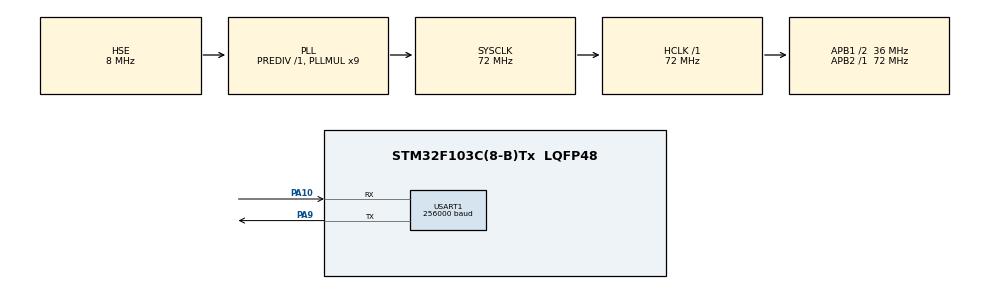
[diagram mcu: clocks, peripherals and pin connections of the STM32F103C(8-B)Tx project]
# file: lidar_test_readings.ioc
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Mcu.Family=STM32F1
Mcu.Name=STM32F103C(8-B)Tx
Mcu.Package=LQFP48
NVIC.PriorityGroup=NVIC_PRIORITYGROUP_4
NVIC.USART1_IRQn=true\:0\:0\:false\:false\:true\:true\:true
PA10.Mode=Asynchronous
PA10.Signal=USART1_RX
PA13.Mode=Serial_Wire
PA13.Signal=SYS_JTMS-SWDIO
PA14.Mode=Serial_Wire
PA14.Signal=SYS_JTCK-SWCLK
PA9.Mode=Asynchronous
PA9.Signal=USART1_TX
PD0-OSC_IN.Mode=HSE-External-Oscillator
PD0-OSC_IN.Signal=RCC_OSC_IN
PD1-OSC_OUT.Mode=HSE-External-Oscillator
PD1-OSC_OUT.Signal=RCC_OSC_OUT
ProjectManager.HeapSize=0x200
ProjectManager.StackSize=0x400
ProjectManager.TargetToolchain=STM32CubeIDE
RCC.AHBFreq_Value=72000000
RCC.APB1CLKDivider=RCC_HCLK_DIV2
RCC.APB1Freq_Value=36000000
RCC.APB1TimFreq_Value=72000000
RCC.APB2Freq_Value=72000000
RCC.APB2TimFreq_Value=72000000
RCC.HCLKFreq_Value=72000000
RCC.PLLMUL=RCC_PLL_MUL9
RCC.PLLSourceVirtual=RCC_PLLSOURCE_HSE
RCC.SYSCLKFreq_VALUE=72000000
RCC.SYSCLKSource=RCC_SYSCLKSOURCE_PLLCLK
RCC.USBFreq_Value=72000000
USART1.BaudRate=256000
USART1.VirtualMode=VM_ASYNC
board=custom

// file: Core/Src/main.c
/* USER CODE BEGIN Header */
/**
  ******************************************************************************
  * @file           : main.c
  * @brief          : Main program body
  ******************************************************************************
  * @attention
  *
  * Copyright (c) 2023 STMicroelectronics.
  * All rights reserved.
  *
  * This software is licensed under terms that can be found in the LICENSE file
  * in the root directory of this software component.
  * If no LICENSE file comes with this software, it is provided AS-IS.
  *
  ******************************************************************************
  */
/* USER CODE END Header */
#include "main.h"
#include "usart.h"
#include "gpio.h"

/* USER CODE BEGIN Includes */
#include "usart_ring.h"
/* USER CODE END Includes */

/* USER CODE BEGIN PD */
#define RESPONSE_BYTES_COUNT 7
#define SCAN_BYTES_COUNT	 5
#define DENSE_MODE
/* USER CODE END PD */

/* USER CODE BEGIN PV */
uint8_t buf[10];
float angle, dist_mm;
usart_ring_t lidar_rx;
/* USER CODE END PV */

void SystemClock_Config(void);

/* USER CODE BEGIN 0 */
void start_scan(void) {
	HAL_UART_StateTypeDef status;
	uint8_t start_cmd[] = {0xA5, 0x20};
	__HAL_UART_DISABLE_IT(&huart1, UART_IT_RXNE);
	HAL_UART_Transmit_IT(&huart1, start_cmd, sizeof(start_cmd));
	do {
		status = HAL_UART_GetState(&huart1);
	} while (status != HAL_UART_STATE_ERROR || status != HAL_UART_STATE_BUSY_TX);
	__HAL_UART_ENABLE_IT(&huart1, UART_IT_RXNE);
}

void stop_scan(void) {
	HAL_UART_StateTypeDef status;
	uint8_t stop_cmd[] = {0xA5, 0x25};
	__HAL_UART_DISABLE_IT(&huart1, UART_IT_RXNE);
	HAL_UART_Transmit_IT(&huart1, stop_cmd, sizeof(stop_cmd));
	do {
		status = HAL_UART_GetState(&huart1);
	} while (status != HAL_UART_STATE_ERROR || status != HAL_UART_STATE_BUSY_TX);
	HAL_Delay(10);
	usart_ring_clear(&lidar_rx);
	__HAL_UART_ENABLE_IT(&huart1, UART_IT_RXNE);
}

void reset_lidar(void) {
	HAL_UART_StateTypeDef status;
	uint8_t reset_cmd[] = {0xA5, 0x40};
	__HAL_UART_DISABLE_IT(&huart1, UART_IT_RXNE);
	HAL_UART_Transmit_IT(&huart1, reset_cmd, sizeof(reset_cmd));
	do {
		status = HAL_UART_GetState(&huart1);
	} while (status != HAL_UART_STATE_ERROR || status != HAL_UART_STATE_BUSY_TX);
	usart_ring_clear(&lidar_rx);
	__HAL_UART_ENABLE_IT(&huart1, UART_IT_RXNE);
}

void get_lidar_values(void) {
	// TODO: нужно взаимодействие с кольцевым буфером
	volatile uint8_t s, not_s;

	while (usart_ring_available(&lidar_rx)) {
		buf[0] = usart_ring_read(&lidar_rx);
		s = buf[0] & 0x01;
		not_s = (buf[0] & 0x02) >> 1;
		if (s != not_s) {
			buf[1] = usart_ring_read(&lidar_rx);
			if (buf[1] & 0x01) { // "c" bit should be equal to 1
				if (buf[0] == 0x0A) {
					for (uint8_t i = 0; i < 3; i++) usart_ring_read(&lidar_rx);
				} else if (buf[0] == 0xBE) {
					for (uint8_t i = 2; i < SCAN_BYTES_COUNT; i++) buf[i] = usart_ring_read(&lidar_rx);
					angle = ((buf[1] >> 1) | (buf[2] << 7)) / 64.0f;
#ifdef DENSE_MODE
					dist_mm = (buf[3] | (buf[4] << 8));
#else
					dist_mm = (buf[3] | (buf[4] << 8)) / 4.0f;
#endif
				}
			}
		}
	}
}
/* USER CODE END 0 */

int main(void)
{

  /* MCU Configuration--------------------------------------------------------*/

  /* Reset of all peripherals, Initializes the Flash interface and the Systick. */
  HAL_Init();

  /* Configure the system clock */
  SystemClock_Config();

  /* Initialize all configured peripherals */
  MX_GPIO_Init();
  MX_USART1_UART_Init();
  /* USER CODE BEGIN 2 */
  __HAL_UART_ENABLE_IT(&huart1, UART_IT_TXE);
  usart_ring_init(&lidar_rx, &huart1, 500);
  start_scan();
  /* USER CODE END 2 */

  /* Infinite loop */
  /* USER CODE BEGIN WHILE */
  while (1) {
	  get_lidar_values();
    /* USER CODE END WHILE */

  }
}

void SystemClock_Config(void)
{
  RCC_OscInitTypeDef RCC_OscInitStruct = {0};
  RCC_ClkInitTypeDef RCC_ClkInitStruct = {0};

  /** Initializes the RCC Oscillators according to the specified parameters
  * in the RCC_OscInitTypeDef structure.
  */
  RCC_OscInitStruct.OscillatorType = RCC_OSCILLATORTYPE_HSE;
  RCC_OscInitStruct.HSEState = RCC_HSE_ON;
  RCC_OscInitStruct.HSEPredivValue = RCC_HSE_PREDIV_DIV1;
  RCC_OscInitStruct.HSIState = RCC_HSI_ON;
  RCC_OscInitStruct.PLL.PLLState = RCC_PLL_ON;
  RCC_OscInitStruct.PLL.PLLSource = RCC_PLLSOURCE_HSE;
  RCC_OscInitStruct.PLL.PLLMUL = RCC_PLL_MUL9;
  if (HAL_RCC_OscConfig(&RCC_OscInitStruct) != HAL_OK)
  {
    Error_Handler();
  }
  /** Initializes the CPU, AHB and APB buses clocks
  */
  RCC_ClkInitStruct.ClockType = RCC_CLOCKTYPE_HCLK|RCC_CLOCKTYPE_SYSCLK
                              |RCC_CLOCKTYPE_PCLK1|RCC_CLOCKTYPE_PCLK2;
  RCC_ClkInitStruct.SYSCLKSource = RCC_SYSCLKSOURCE_PLLCLK;
  RCC_ClkInitStruct.AHBCLKDivider = RCC_SYSCLK_DIV1;
  RCC_ClkInitStruct.APB1CLKDivider = RCC_HCLK_DIV2;
  RCC_ClkInitStruct.APB2CLKDivider = RCC_HCLK_DIV1;

  if (HAL_RCC_ClockConfig(&RCC_ClkInitStruct, FLASH_LATENCY_2) != HAL_OK)
  {
    Error_Handler();
  }
}

void Error_Handler(void)
{
  __disable_irq();
  while (1)
  {
  }
}
